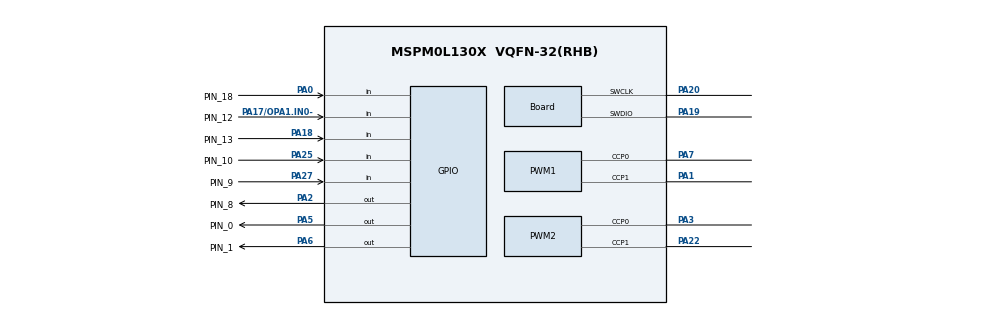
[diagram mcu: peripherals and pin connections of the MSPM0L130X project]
/**
 * @cliArgs --device "MSPM0L130X" --part "Default" --package "VQFN-32(RHB)" --product "mspm0_sdk@2.04.00.06"
 * @versions {"tool":"1.23.0+4000"}
 */

/**
 * Import the modules used in this configuration.
 */
const Board   = scripting.addModule("/ti/driverlib/Board");
const GPIO    = scripting.addModule("/ti/driverlib/GPIO", {}, false);
const GPIO1   = GPIO.addInstance();
const GPIO2   = GPIO.addInstance();
const GPIO3   = GPIO.addInstance();
const GPIO4   = GPIO.addInstance();
const GPIO5   = GPIO.addInstance();
const GPIO6   = GPIO.addInstance();
const GPIO7   = GPIO.addInstance();
const GPIO8   = GPIO.addInstance();
const GPIO9   = GPIO.addInstance();
const GPIO10  = GPIO.addInstance();
const GPIO11  = GPIO.addInstance();
const PWM     = scripting.addModule("/ti/driverlib/PWM", {}, false);
const PWM1    = PWM.addInstance();
const PWM2    = PWM.addInstance();
const SYSCTL  = scripting.addModule("/ti/driverlib/SYSCTL");
const SYSTICK = scripting.addModule("/ti/driverlib/SYSTICK");
const TIMER   = scripting.addModule("/ti/driverlib/TIMER", {}, false);
const TIMER1  = TIMER.addInstance();

/**
 * Write custom configuration values to the imported modules.
 */
const gate6  = system.clockTree["MFCLKGATE"];
gate6.enable = true;

Board.peripheral.swclkPin.$assign = "PA20";
Board.peripheral.swdioPin.$assign = "PA19";

GPIO1.$name                              = "AIN1";
GPIO1.port                               = "PORTA";
GPIO1.associatedPins.create(2);
GPIO1.associatedPins[0].$name            = "PIN_0";
GPIO1.associatedPins[0].assignedPin      = "5";
GPIO1.associatedPins[0].internalResistor = "PULL_UP";
GPIO1.associatedPins[0].driveStrength    = "HIGH";
GPIO1.associatedPins[0].hiZ              = "ENABLE";
GPIO1.associatedPins[0].pin.$assign      = "PA5";
GPIO1.associatedPins[1].$name            = "PIN_1";
GPIO1.associatedPins[1].assignedPin      = "6";
GPIO1.associatedPins[1].pin.$assign      = "PA6";

GPIO2.$name                         = "BIN";
GPIO2.port                          = "PORTA";
GPIO2.associatedPins.create(2);
GPIO2.associatedPins[0].$name       = "PIN_2";
GPIO2.associatedPins[0].assignedPin = "15";
GPIO2.associatedPins[1].$name       = "PIN_3";
GPIO2.associatedPins[1].assignedPin = "16";

GPIO3.$name                         = "AIN2";
GPIO3.port                          = "PORTA";
GPIO3.associatedPins.create(2);
GPIO3.associatedPins[0].$name       = "PIN_4";
GPIO3.associatedPins[0].assignedPin = "11";
GPIO3.associatedPins[1].$name       = "PIN_5";
GPIO3.associatedPins[1].assignedPin = "10";

GPIO4.$name                         = "BIN0";
GPIO4.port                          = "PORTA";
GPIO4.associatedPins.create(2);
GPIO4.associatedPins[0].$name       = "PIN_6";
GPIO4.associatedPins[0].assignedPin = "8";
GPIO4.associatedPins[1].$name       = "PIN_7";
GPIO4.associatedPins[1].assignedPin = "9";

GPIO5.$name                         = "xuj_out1";
GPIO5.port                          = "PORTA";
GPIO5.associatedPins[0].$name       = "PIN_9";
GPIO5.associatedPins[0].assignedPin = "27";
GPIO5.associatedPins[0].direction   = "INPUT";
GPIO5.associatedPins[0].pin.$assign = "PA27";

GPIO6.$name                         = "xuj_out2";
GPIO6.port                          = "PORTA";
GPIO6.associatedPins[0].$name       = "PIN_10";
GPIO6.associatedPins[0].assignedPin = "25";
GPIO6.associatedPins[0].direction   = "INPUT";
GPIO6.associatedPins[0].pin.$assign = "PA25";

GPIO7.$name                         = "xuj_out3";
GPIO7.port                          = "PORTA";
GPIO7.associatedPins[0].$name       = "PIN_11";
GPIO7.associatedPins[0].assignedPin = "24";
GPIO7.associatedPins[0].direction   = "INPUT";

GPIO8.$name                         = "xuj_out4";
GPIO8.port                          = "PORTA";
GPIO8.associatedPins[0].$name       = "PIN_12";
GPIO8.associatedPins[0].assignedPin = "17";
GPIO8.associatedPins[0].direction   = "INPUT";
GPIO8.associatedPins[0].pin.$assign = "PA17/OPA1.IN0-";

GPIO9.$name                         = "xuj_out5";
GPIO9.port                          = "PORTA";
GPIO9.associatedPins[0].$name       = "PIN_13";
GPIO9.associatedPins[0].direction   = "INPUT";
GPIO9.associatedPins[0].assignedPin = "18";
GPIO9.associatedPins[0].pin.$assign = "PA18";

GPIO10.$name                              = "BUZZER";
GPIO10.port                               = "PORTA";
GPIO10.associatedPins[0].$name            = "PIN_8";
GPIO10.associatedPins[0].initialValue     = "SET";
GPIO10.associatedPins[0].ioStructure      = "SD";
GPIO10.associatedPins[0].internalResistor = "PULL_DOWN";
GPIO10.associatedPins[0].assignedPin      = "2";
GPIO10.associatedPins[0].pin.$assign      = "PA2";

GPIO11.$name                         = "KEY";
GPIO11.port                          = "PORTA";
GPIO11.associatedPins[0].$name       = "PIN_18";
GPIO11.associatedPins[0].direction   = "INPUT";
GPIO11.associatedPins[0].polarity    = "RISE_FALL";
GPIO11.associatedPins[0].assignedPin = "0";
GPIO11.associatedPins[0].interruptEn = true;
GPIO11.associatedPins[0].pin.$assign = "PA0";

PWM1.$name                      = "PWM_0";
PWM1.dutyArgs                   = "[25,75,0,0]";
PWM1.clockPrescale              = 32;
PWM1.clockDivider               = 4;
PWM1.pwmMode                    = "EDGE_ALIGN_UP";
PWM1.peripheral.$assign         = "TIMG1";
PWM1.peripheral.ccp0Pin.$assign = "PA7";
PWM1.peripheral.ccp1Pin.$assign = "PA1";
PWM1.PWM_CHANNEL_0.$name        = "ti_driverlib_pwm_PWMTimerCC0";
PWM1.PWM_CHANNEL_0.dutyCycle    = 50;
PWM1.PWM_CHANNEL_1.$name        = "ti_driverlib_pwm_PWMTimerCC1";
PWM1.PWM_CHANNEL_1.dutyCycle    = 30;
PWM1.ccp0PinConfig.$name        = "ti_driverlib_gpio_GPIOPinGeneric0";
PWM1.ccp1PinConfig.$name        = "ti_driverlib_gpio_GPIOPinGeneric1";

PWM2.$name                      = "PWM_1";
PWM2.pwmMode                    = "EDGE_ALIGN_UP";
PWM2.clockDivider               = 4;
PWM2.peripheral.$assign         = "TIMG2";
PWM2.peripheral.ccp0Pin.$assign = "PA3";
PWM2.peripheral.ccp1Pin.$assign = "PA22";
PWM2.PWM_CHANNEL_0.$name        = "ti_driverlib_pwm_PWMTimerCC2";
PWM2.PWM_CHANNEL_0.dutyCycle    = 50;
PWM2.PWM_CHANNEL_1.$name        = "ti_driverlib_pwm_PWMTimerCC3";
PWM2.PWM_CHANNEL_1.dutyCycle    = 80;
PWM2.ccp0PinConfig.$name        = "ti_driverlib_gpio_GPIOPinGeneric2";
PWM2.ccp1PinConfig.$name        = "ti_driverlib_gpio_GPIOPinGeneric3";


SYSTICK.periodEnable    = true;
SYSTICK.interruptEnable = true;
SYSTICK.systickEnable   = true;
SYSTICK.period          = 32000;

TIMER1.$name                            = "TIMER_0";
TIMER1.timerClkDiv                      = 8;
TIMER1.timerClkPrescale                 = 40;
TIMER1.timerPeriod                      = "1 ms";
TIMER1.interrupts                       = ["ZERO"];
TIMER1.peripheral.$assignAllowConflicts = "TIMG0";

/**
 * Pinmux solution for unlocked pins/peripherals. This ensures that minor changes to the automatic solver in a future
 * version of the tool will not impact the pinmux you originally saw.  These lines can be completely deleted in order to
 * re-solve from scratch.
 */
Board.peripheral.$suggestSolution            = "DEBUGSS";
GPIO2.associatedPins[0].pin.$suggestSolution = "PA15";
GPIO2.associatedPins[1].pin.$suggestSolution = "PA16";
GPIO3.associatedPins[0].pin.$suggestSolution = "PA11";
GPIO3.associatedPins[1].pin.$suggestSolution = "PA10";
GPIO4.associatedPins[0].pin.$suggestSolution = "PA8";
GPIO4.associatedPins[1].pin.$suggestSolution = "PA9";
GPIO7.associatedPins[0].pin.$suggestSolution = "PA24/OPA0.IN0-";
SYSCTL.peripheral.$suggestSolution           = "SYSCTL";
